# M4G8 register map
File version: 0.1
Registers are 32-bit, read-write, reset 0x0 unless marked. A register's access mark holds for its fields unless they carry their own. Offsets are from the block's base; [hi:lo] are bit positions; {n}, {i} and the like mark numbered series.

## LTT — Long Term Timer(LTTMR)
Base 0x4003FF00
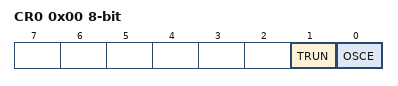
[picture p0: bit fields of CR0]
0x00 CR0 8-bit — Long Term Control Register
  [1] TRUN, [0] OSCE
0x01 VALL 8-bit — Long Term Setting Register
  [7:0] TMRVALL
0x02 VALH 8-bit — Long Term Setting Register
  [7:0] TMRVALH

## TSPI0 — Serial Interface (TSPI)
Base 0x4006A000
Same registers: TSPI1 0x4006A400, TSPI2 0x4006A800, TSPI3 0x4006AC00, TSPI4 0x4006B000, TSPI5 0x4006B400, TSPI6 0x400CB800, TSPI7 0x400CBC00, TSPI8 0x400CC000
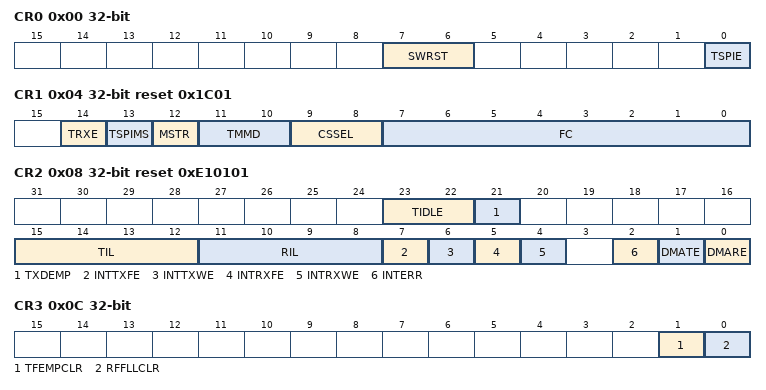
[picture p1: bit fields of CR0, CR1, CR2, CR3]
0x00 CR0 — TSPI Control Register 0
  [7:6] SWRST wo, [0] TSPIE
0x04 CR1 reset 0x1C01 — TSPI Control Register 1
  [14] TRXE, [13] TSPIMS, [12] MSTR, [11:10] TMMD, [9:8] CSSEL, [7:0] FC
0x08 CR2 reset 0xE10101 — TSPI Control Register 2
  [23:22] TIDLE, [21] TXDEMP, [15:12] TIL, [11:8] RIL, [7] INTTXFE, [6] INTTXWE, [5] INTRXFE, [4] INTRXWE, [2] INTERR, [1] DMATE, [0] DMARE
0x0C CR3 — TSPI Control Register 3
  [1] TFEMPCLR wo, [0] RFFLLCLR wo
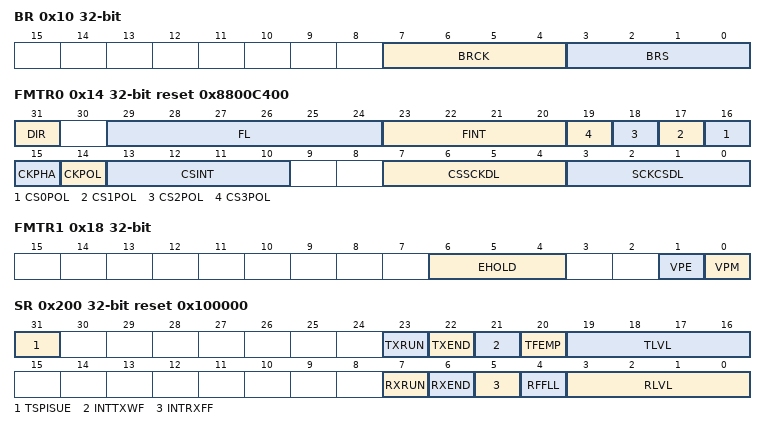
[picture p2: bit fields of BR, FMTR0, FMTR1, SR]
0x10 BR — TSPI Baud Rate Generator Control Register
  [7:4] BRCK, [3:0] BRS
0x14 FMTR0 reset 0x8800C400 — TSPI Format Control Register 0
  [31] DIR, [29:24] FL, [23:20] FINT, [n+16] CS{n}POL (n=0..3), [15] CKPHA ro, [14] CKPOL, [13:10] CSINT, [7:4] CSSCKDL, [3:0] SCKCSDL
0x18 FMTR1 — TSPI Format Control Register 1
  [6:4] EHOLD, [1] VPE, [0] VPM
0x100 DR — TSPI Data Register
  [31:0] TSPIDR
0x200 SR reset 0x100000 — TSPI Status Register
  [31] TSPISUE ro, [23] TXRUN ro, [22] TXEND, [21] INTTXWF, [20] TFEMP ro, [19:16] TLVL ro, [7] RXRUN ro, [6] RXEND, [5] INTRXFF, [4] RFFLL ro, [3:0] RLVL ro
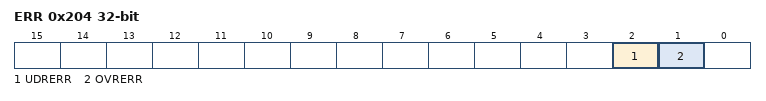
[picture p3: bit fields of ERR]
0x204 ERR — TSPI Parity Error Flag Register
  [2] UDRERR, [1] OVRERR

## EXB — External Bus Interface(EXB)
Base 0x40076000
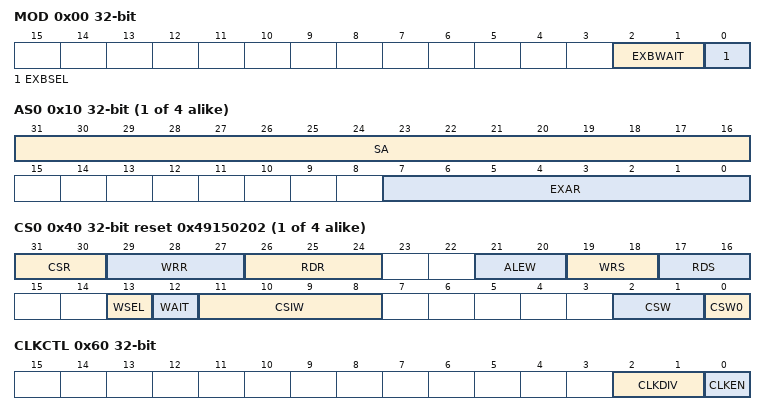
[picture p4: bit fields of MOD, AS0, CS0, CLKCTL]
0x00 MOD — External Bus Mode Control Register
  [2:1] EXBWAIT, [0] EXBSEL
{0x10+4i} AS{i} (i=0..3) — External Bus Base Address and CS Space setting Register {i}
  [31:16] SA, [7:0] EXAR
{0x40+4i} CS{i} reset 0x49150202 (i=0..3) — Chip Select and Wait Controller Register {i}
  [31:30] CSR, [29:27] WRR, [26:24] RDR, [21:20] ALEW, [19:18] WRS, [17:16] RDS, [13] WSEL, [12] WAIT, [11:8] CSIW, [2:1] CSW, [0] CSW0
0x60 CLKCTL — Clock output controlRegister
  [2:1] CLKDIV, [0] CLKEN

## CG — Clock Generator (CG)
Base 0x40083000
0x00 PROTECT reset 0xC1
  [7:0] PROTECT
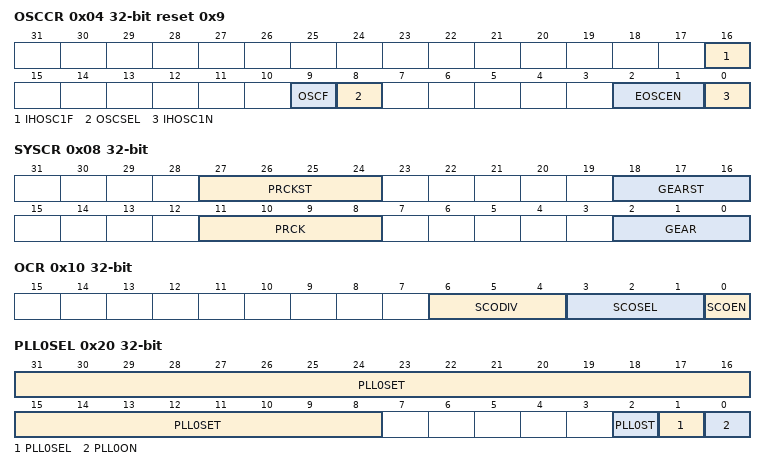
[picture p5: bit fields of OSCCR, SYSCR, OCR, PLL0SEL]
0x04 OSCCR reset 0x9 — Oscillation Control Register
  [16] IHOSC1F ro, [9] OSCF ro, [8] OSCSEL, [2:1] EOSCEN ro, [0] IHOSC1N
0x08 SYSCR — System Clock Control Register
  [27:24] PRCKST ro, [18:16] GEARST ro, [11:8] PRCK, [2:0] GEAR
0x0C STBYCR — Standby Control Register
  [1:0] STBY
0x10 OCR — SCOUT Output Control Register
  [6:4] SCODIV, [3:1] SCOSEL, [0] SCOEN
0x20 PLL0SEL — PLL Selection Register 0
  [31:8] PLL0SET, [2] PLL0ST ro, [1] PLL0SEL, [0] PLL0ON
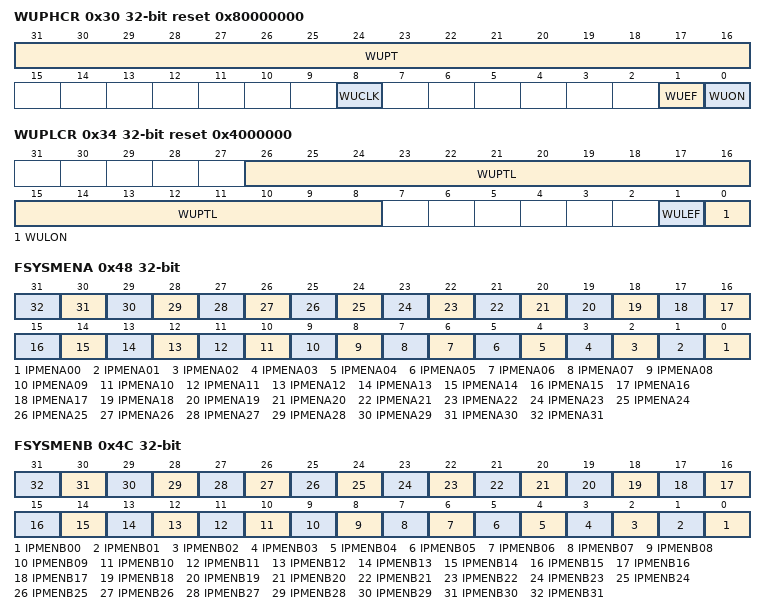
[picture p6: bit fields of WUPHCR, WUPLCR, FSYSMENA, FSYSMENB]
0x30 WUPHCR reset 0x80000000 — High OSC Warming-up Register
  [31:16] WUPT, [8] WUCLK, [1] WUEF ro, [0] WUON wo
0x34 WUPLCR reset 0x4000000 — Low OSC Warming-up Register
  [26:8] WUPTL, [1] WULEF ro, [0] WULON wo
0x48 FSYSMENA — Middle fsys Supply Stop Register A
  [n] IPMENA{n:02} (n=0..31)
0x4C FSYSMENB — Middle fsys Supply Stop Register A
  [n] IPMENB{n:02} (n=0..31)
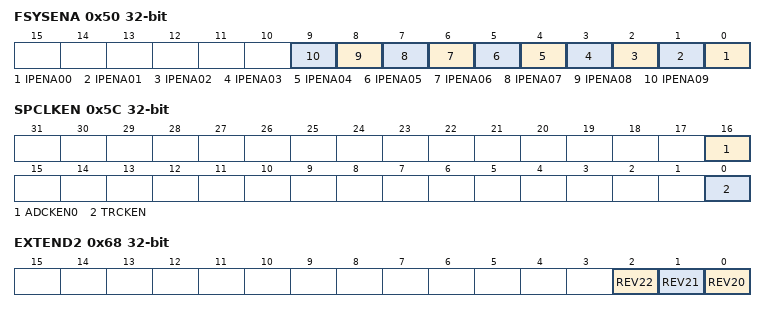
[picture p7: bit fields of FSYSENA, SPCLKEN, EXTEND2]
0x50 FSYSENA — High fsys Supply Stop Register A
  [n] IPENA{n:02} (n=0..9)
0x5C SPCLKEN — ADC TRACE Clock Supply Stop Register
  [16] ADCKEN0, [0] TRCKEN
0x68 EXTEND2 — Extend for MDMAC Register
  [2] REV22, [1] REV21, [0] REV20

## IB — Interrupt Control B Register
Base 0x40083200
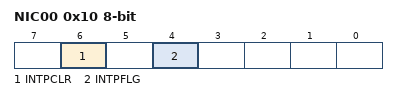
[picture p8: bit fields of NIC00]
0x10 NIC00 8-bit (reset mask 0xBF) — Non maskable Interrupu Control Register 00
  [6] INTPCLR wo, [4] INTPFLG
{0x60+i} IMC{i:03} 8-bit (i=0..141) — Interrupu Mode Control Register 000
  [0] INTEN

## IMN — Interrupt Monitor Register
Base 0x40083300
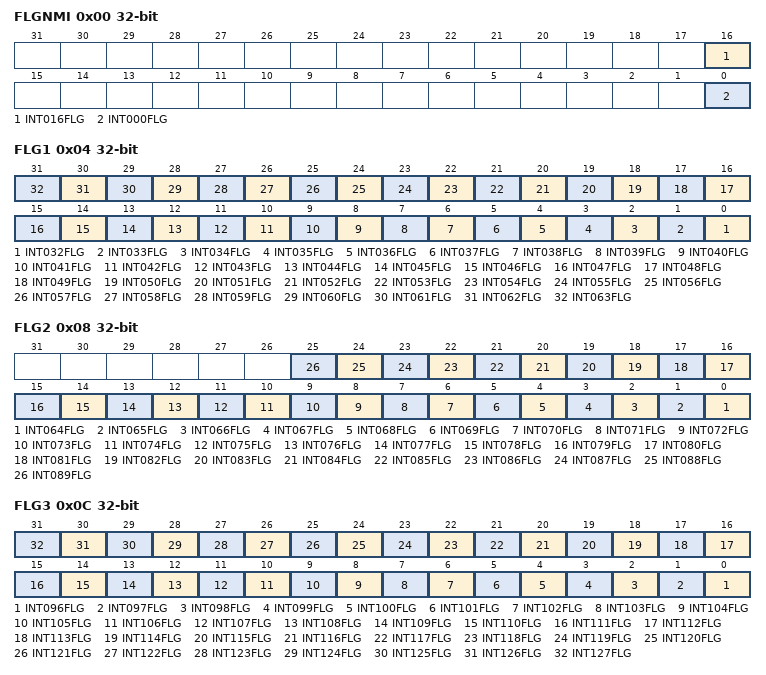
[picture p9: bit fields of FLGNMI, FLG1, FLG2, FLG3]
0x00 FLGNMI ro — NMI Interrupt Monitor Flag 0
  [16] INT016FLG, [0] INT000FLG
0x04 FLG1 ro — Interrupt Monitor Flag 1 (032 - 063)
  [n-32] INT{n:03}FLG (n=32..63)
0x08 FLG2 ro — Interrupt Monitor Flag 2 (064 - 095)
  [n-64] INT{n:03}FLG (n=64..89)
0x0C FLG3 ro — Interrupt Monitor Flag 3 (096 - 127)
  [n-96] INT{n:03}FLG (n=96..127)
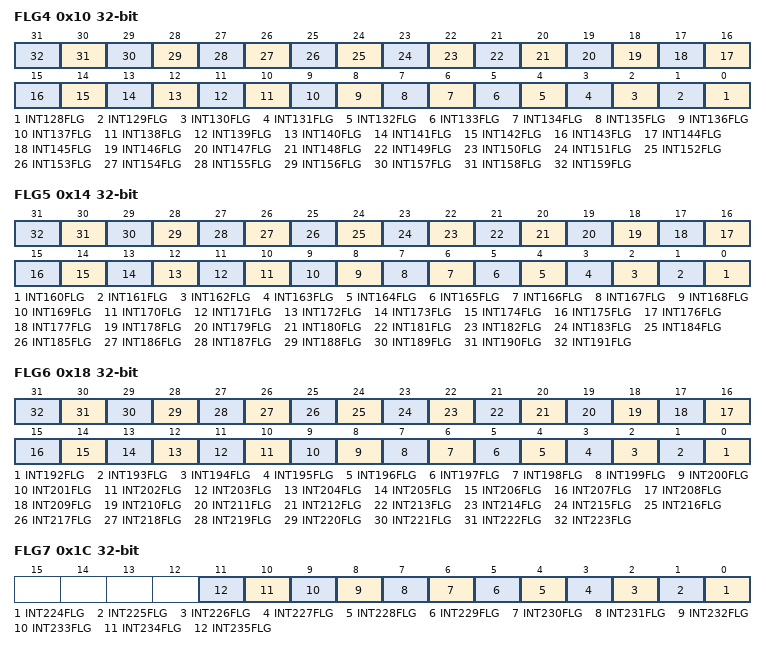
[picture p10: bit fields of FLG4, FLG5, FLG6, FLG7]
0x10 FLG4 ro — Interrupt Monitor Flag 4 (128 - 159)
  [n-128] INT{n}FLG (n=128..159)
0x14 FLG5 ro — Interrupt Monitor Flag 5 (160 - 191)
  [n-160] INT{n}FLG (n=160..191)
0x18 FLG6 ro — Interrupt Monitor Flag 6 (192 - 223)
  [n-192] INT{n}FLG (n=192..223)
0x1C FLG7 ro — Interrupt Monitor Flag 7 (224 - 225)
  [n-224] INT{n}FLG (n=224..235)
